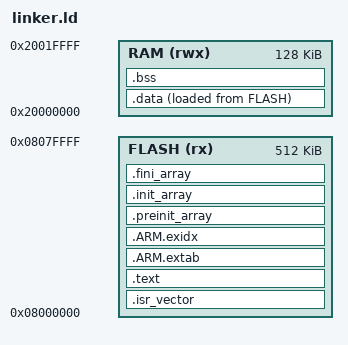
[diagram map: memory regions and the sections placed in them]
ENTRY(Reset_Handler)

MEMORY
{
  FLASH (rx) : ORIGIN = 0x08000000, LENGTH = 512K
  RAM (rwx)  : ORIGIN = 0x20000000, LENGTH = 128K
}

_estack = ORIGIN(RAM) + LENGTH(RAM);
_Min_Stack_Size = 0x800; /* Reserva minima de 2 KB para a pilha. */

SECTIONS
{
  .isr_vector :
  {
    . = ALIGN(512);
    KEEP(*(.isr_vector))
    . = ALIGN(4);
  } > FLASH

  .text :
  {
    . = ALIGN(4);
    *(.text .text.*)
    *(.rodata .rodata.*)
    KEEP(*(.init))
    KEEP(*(.fini))
    . = ALIGN(4);
  } > FLASH

  .ARM.extab :
  {
    *(.ARM.extab* .gnu.linkonce.armextab.*)
  } > FLASH

  .ARM.exidx :
  {
    __exidx_start = .;
    *(.ARM.exidx*)
    __exidx_end = .;
  } > FLASH

  .preinit_array :
  {
    . = ALIGN(4);
    PROVIDE_HIDDEN(__preinit_array_start = .);
    KEEP(*(.preinit_array*))
    PROVIDE_HIDDEN(__preinit_array_end = .);
  } > FLASH

  .init_array :
  {
    . = ALIGN(4);
    PROVIDE_HIDDEN(__init_array_start = .);
    KEEP(*(SORT(.init_array.*)))
    KEEP(*(.init_array))
    PROVIDE_HIDDEN(__init_array_end = .);
  } > FLASH

  .fini_array :
  {
    . = ALIGN(4);
    PROVIDE_HIDDEN(__fini_array_start = .);
    KEEP(*(SORT(.fini_array.*)))
    KEEP(*(.fini_array))
    PROVIDE_HIDDEN(__fini_array_end = .);
  } > FLASH

  /* Valores iniciais guardados na Flash e copiados para a RAM pelo startup. */
  _sidata = LOADADDR(.data);
  .data :
  {
    . = ALIGN(4);
    _sdata = .;
    *(.data .data.*)
    . = ALIGN(4);
    _edata = .;
  } > RAM AT > FLASH

  /* Variaveis sem inicializador: zeradas pelo startup, sem ocupar Flash. */
  .bss (NOLOAD) :
  {
    . = ALIGN(4);
    _sbss = .;
    *(.bss .bss.*)
    *(COMMON)
    . = ALIGN(4);
    _ebss = .;
  } > RAM

  . = ALIGN(8);
  _end = .;
  PROVIDE(end = .);
  _stack_limit = _estack - _Min_Stack_Size;
  ASSERT(_end <= _stack_limit, "RAM insuficiente para dados e reserva da pilha")
}
